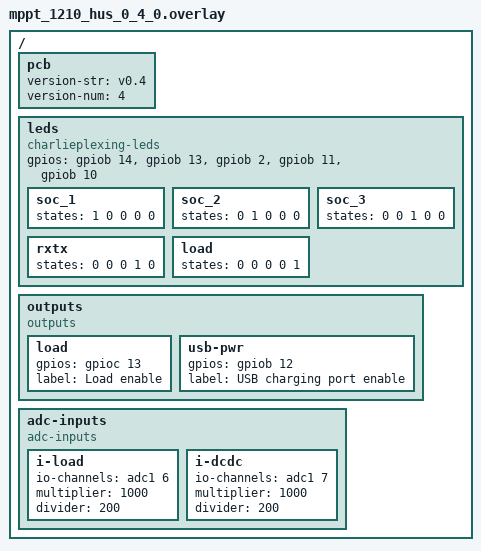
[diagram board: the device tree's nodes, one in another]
/*
 * SPDX-License-Identifier: Apache-2.0
 *
 * Copyright (c) 2020 Martin Jäger / Libre Solar
 */

/ {
	pcb {
		version-str = "v0.4";
		version-num = <4>;
	};

	leds {
		compatible = "charlieplexing-leds";
		gpios = <&gpiob 14 GPIO_ACTIVE_HIGH>,	/* GND */
			<&gpiob 13 GPIO_ACTIVE_HIGH>,	/* SOC_12 */
			<&gpiob  2 GPIO_ACTIVE_HIGH>,	/* SOC_3 */
			<&gpiob 11 GPIO_ACTIVE_HIGH>,	/* RXTX */
			<&gpiob 10 GPIO_ACTIVE_HIGH>;	/* LOAD */

		soc_1 {
			states = <1 0 0 0 0>;
		};

		soc_2 {
			states = <0 1 0 0 0>;
		};

		soc_3 {
			states = <0 0 1 0 0>;
		};

		rxtx {
			states = <0 0 0 1 0>;
		};

		load {
			states = <0 0 0 0 1>;
		};
	};

	outputs {
		compatible = "outputs";

		load {
			gpios = <&gpioc 13 GPIO_ACTIVE_HIGH>;
			label = "Load enable";
		};

		usb-pwr {
			gpios = <&gpiob 12 GPIO_ACTIVE_HIGH>;
			label = "USB charging port enable";
		};

		/delete-node/ v-solar;
		/delete-node/ boot0;
	};

	adc-inputs {
		compatible = "adc-inputs";

		i-load {
			io-channels = <&adc1 6>;
			// amp gain: 50, resistor: 4 mOhm
			multiplier = <1000>;
			divider = <200>;	// 4*50
		};

		i-dcdc {
			io-channels = <&adc1 7>;
			// amp gain: 50, resistor: 4 mOhm
			multiplier = <1000>;
			divider = <200>;	// 4*50
		};

		/delete-node/ temp-bat;
	};
};
